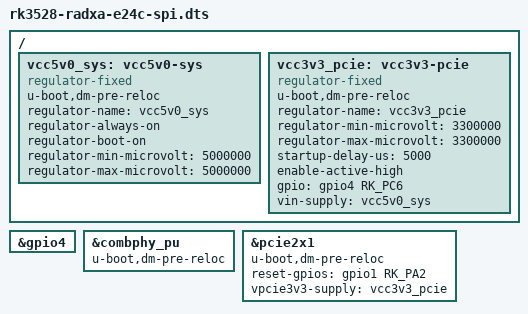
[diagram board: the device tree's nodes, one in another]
/*
 * SPDX-License-Identifier:     GPL-2.0+
 *
 * Copyright (c) 2024 Rockchip Electronics Co., Ltd.
 * Copyright (c) 2024 Radxa Computer (Shenzhen) Co., Ltd.
 *
 */

/dts-v1/;
#include "rk3528-rock-2.dts"

/ {
	vcc5v0_sys: vcc5v0-sys {
		u-boot,dm-pre-reloc;
		compatible = "regulator-fixed";
		regulator-name = "vcc5v0_sys";
		regulator-always-on;
		regulator-boot-on;
		regulator-min-microvolt = <5000000>;
		regulator-max-microvolt = <5000000>;
	};

	vcc3v3_pcie: vcc3v3-pcie {
		u-boot,dm-pre-reloc;
		compatible = "regulator-fixed";
		regulator-name = "vcc3v3_pcie";
		regulator-min-microvolt = <3300000>;
		regulator-max-microvolt = <3300000>;
		startup-delay-us = <5000>;
		enable-active-high;
		gpio = <&gpio4 RK_PC6 GPIO_ACTIVE_HIGH>;
		vin-supply = <&vcc5v0_sys>;
	};
};

&gpio4 {
	u-boot,dm-spl;
};

&combphy_pu {
	u-boot,dm-pre-reloc;
	status = "okay";
};

&pcie2x1 {
	u-boot,dm-pre-reloc;
	reset-gpios = <&gpio1 RK_PA2 GPIO_ACTIVE_HIGH>;
	vpcie3v3-supply = <&vcc3v3_pcie>;
	status = "okay";
};
